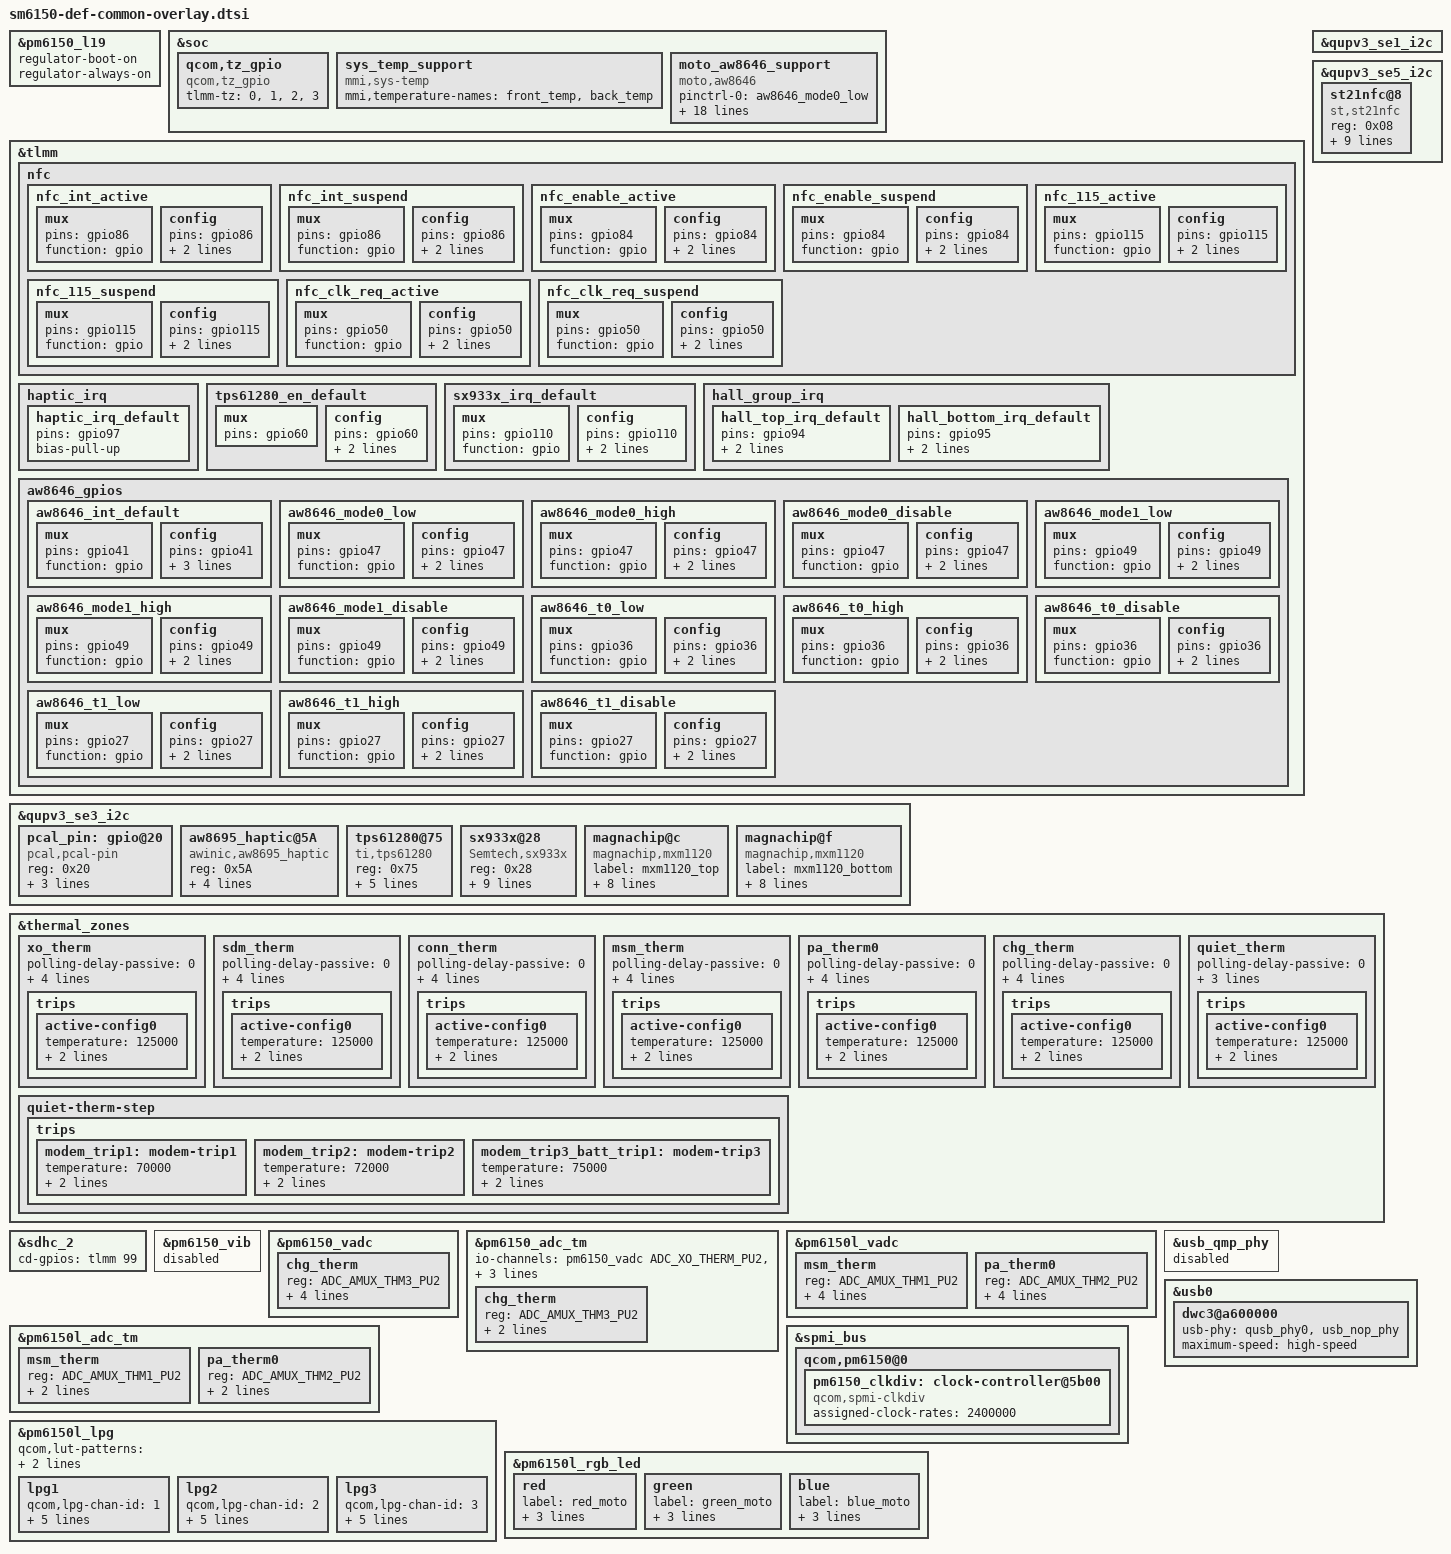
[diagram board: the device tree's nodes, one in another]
/* Copyright (c) 2018, The Linux Foundation. All rights reserved.
 *
 * This program is free software; you can redistribute it and/or modify
 * it under the terms of the GNU General Public License version 2 and
 * only version 2 as published by the Free Software Foundation.
 *
 * This program is distributed in the hope that it will be useful,
 * but WITHOUT ANY WARRANTY; without even the implied warranty of
 * MERCHANTABILITY or FITNESS FOR A PARTICULAR PURPOSE.  See the
 * GNU General Public License for more details.
 */

#include "sm6150-moto-common-overlay.dtsi"
#include "sm6150-audio-overlay.dtsi"
#include "sm6150-def-audio-overlay.dtsi"
#include "sm6150-camera-sensor-mot-def-overlay.dtsi"
#include "sm6150-def-touch-overlay.dtsi"
#include "sm6150-def-fps-overlay.dtsi"
#include "defender-panel.dtsi"

&pm6150_l19 {
	regulator-boot-on;
	regulator-always-on;
	status = "ok";
};

&soc {
	qcom,tz_gpio {
		compatible = "qcom,tz_gpio";
		tlmm-tz = <0>,
			<1>,
			<2>,
			<3>;
	};
};

&tlmm{
	nfc {
		nfc_int_active: nfc_int_active {
			/* active state */
			mux {
				/* GPIO86 NFC Read Interrupt */
				pins = "gpio86";
				function = "gpio";
			};

			config {
				pins = "gpio86";
				bias-disable;
				input-enable;
			};
		};

		nfc_int_suspend: nfc_int_suspend {
			/* sleep state */
			mux {
				/* GPIO 86 NFC Read Interrupt */
				pins = "gpio86";
				function = "gpio";
			};

			config {
				pins = "gpio86";
				bias-disable;
				input-enable;
			};
		};

		nfc_enable_active: nfc_enable_active {
			/* active state */
			mux {
				/* 84: NFC ENABLE */
				pins = "gpio84";
				function = "gpio";
			};

			config {
				pins = "gpio84";
				drive-strength = <2>; /* 2 MA */
				bias-disable;
			};
		};

		nfc_enable_suspend: nfc_enable_suspend {
			/* sleep state */
			mux {
				/* 84: NFC ENABLE */
				pins = "gpio84";
				function = "gpio";
			};

			config {
				pins = "gpio84";
				drive-strength = <2>; /* 2 MA */
				bias-disable;
			};
		};

		nfc_115_active: nfc_115_active {
			/* active state */
			mux {
				/* 84: NFC ENABLE */
				pins = "gpio115";
				function = "gpio";
			};

			config {
				pins = "gpio115";
				drive-strength = <2>; /* 2 MA */
				output-high;
			};
		};

		nfc_115_suspend: nfc_115_suspend {
			/* sleep state */
			mux {
				/* 84: NFC ENABLE */
				pins = "gpio115";
				function = "gpio";
			};

			config {
				pins = "gpio115";
				drive-strength = <2>; /* 2 MA */
				output-high;
			};
		};

		nfc_clk_req_active: nfc_clk_req_active {
			/* active state */
			mux {
				/* 50: NFC CLOCK REQUEST */
				pins = "gpio50";
				function = "gpio";
			};

			config {
				pins = "gpio50";
				bias-disable;
				input-enable;
			};
		};

		nfc_clk_req_suspend: nfc_clk_req_suspend {
			/* sleep state */
			mux {
				/* 50: NFC CLOCK REQUEST */
				pins = "gpio50";
				function = "gpio";
			};

			config {
				pins = "gpio50";
				bias-disable;
				input-enable;
			};
		};
	};

	haptic_irq {
		haptic_irq_default: haptic_irq_default {
			pins = "gpio97";
			bias-pull-up;
		};
	};

        tps61280_en_default: tps61280_en_default {
               mux {
                        pins = "gpio60";
               };
               config {
                        pins = "gpio60";
                        drive_strength = <16>;
                        output-high;
              };
        };

	sx933x_irq_default: sx933x_irq_default {
		mux {
			pins = "gpio110";
			function = "gpio";
		};
		config {
			pins = "gpio110";
			drive-strength = <8>;
			bias-pull-up;
		};
	};

	hall_group_irq {
		hall_top_irq_default: hall_top_irq_default {
			pins = "gpio94";
			drive-strength = <6>;
			bias-pull-up;
		};
		hall_bottom_irq_default: hall_bottom_irq_default {
			pins = "gpio95";
			drive-strength = <6>;
			bias-pull-up;
		};
	};

	aw8646_gpios {
		aw8646_int_default: aw8646_int_default {
			mux {
				pins = "gpio41";
				function = "gpio";
			};

			config {
				pins = "gpio41";
				drive-strength = <6>;
				input-enable;
				bias-disable;
			};
		};
		aw8646_mode0_low: aw8646_mode0_low{
			mux {
				pins = "gpio47";
				function = "gpio";
			};

			config {
				pins = "gpio47";
				drive-strength = <2>; /* 2 MA */
				output-low;
			};
		};
		aw8646_mode0_high: aw8646_mode0_high{
			mux {
				pins = "gpio47";
				function = "gpio";
			};

			config {
				pins = "gpio47";
				drive-strength = <2>; /* 2 MA */
				output-high;
			};
		};
		aw8646_mode0_disable: aw8646_mode0_disable {
			mux {
				pins = "gpio47";
				function = "gpio";
			};

			config {
				pins = "gpio47";
				input-enable;
				bias-disable;
			};
		};
		aw8646_mode1_low: aw8646_mode1_low {
			mux {
				pins = "gpio49";
				function = "gpio";
			};

			config {
				pins = "gpio49";
				drive-strength = <2>; /* 2 MA */
				output-low;
			};
		};
		aw8646_mode1_high: aw8646_mode1_high {
			mux {
				pins = "gpio49";
				function = "gpio";
			};

			config {
				pins = "gpio49";
				drive-strength = <2>; /* 2 MA */
				output-high;
			};
		};
		aw8646_mode1_disable: aw8646_mode1_disable {
			mux {
				pins = "gpio49";
				function = "gpio";
			};

			config {
				pins = "gpio49";
				input-enable;
				bias-disable;
			};
		};
		aw8646_t0_low: aw8646_t0_low {
			mux {
				pins = "gpio36";
				function = "gpio";
			};

			config {
				pins = "gpio36";
				drive-strength = <2>; /* 2 MA */
				output-low;
			};
		};
		aw8646_t0_high: aw8646_t0_high {
			mux {
				pins = "gpio36";
				function = "gpio";
			};

			config {
				pins = "gpio36";
				drive-strength = <2>; /* 2 MA */
				output-high;
			};
		};
		aw8646_t0_disable: aw8646_t0_disable {
			mux {
				pins = "gpio36";
				function = "gpio";
			};

			config {
				pins = "gpio36";
				input-enable;
				bias-disable;
			};
		};
		aw8646_t1_low: aw8646_t1_low {
			mux {
				pins = "gpio27";
				function = "gpio";
			};

			config {
				pins = "gpio27";
				drive-strength = <2>; /* 2 MA */
				output-low;
			};
		};
		aw8646_t1_high: aw8646_t1_high {
			mux {
				pins = "gpio27";
				function = "gpio";
			};

			config {
				pins = "gpio27";
				drive-strength = <2>; /* 2 MA */
				output-high;
			};
		};
		aw8646_t1_disable: aw8646_t1_disable {
			mux {
				pins = "gpio27";
				function = "gpio";
			};

			config {
				pins = "gpio27";
				input-enable;
				bias-disable;
			};
		};
	};
};

&soc {
	sys_temp_support {
		compatible = "mmi,sys-temp";
		mmi,temperature-names = "front_temp",
			"back_temp";
		status = "ok";
	};

	moto_aw8646_support {
		compatible = "moto,aw8646";
		status = "ok";
		pinctrl-names = "m0_low", "m0_high", "m0_disable",
						"m1_low", "m1_high", "m1_disable",
						"t0_low", "t0_high", "t0_disable",
						"t1_low", "t1_high", "t1_disable",
						"aw8646_int_default";
		pinctrl-0 = <&aw8646_mode0_low>;
		pinctrl-1 = <&aw8646_mode0_high>;
		pinctrl-2 = <&aw8646_mode0_disable>;
		pinctrl-3 = <&aw8646_mode1_low>;
		pinctrl-4 = <&aw8646_mode1_high>;
		pinctrl-5 = <&aw8646_mode1_disable>;
		pinctrl-6 = <&aw8646_t0_low>;
		pinctrl-7 = <&aw8646_t0_high>;
		pinctrl-8 = <&aw8646_t0_disable>;
		pinctrl-9 = <&aw8646_t1_low>;
		pinctrl-10 = <&aw8646_t1_high>;
		pinctrl-11 = <&aw8646_t1_disable>;
		pinctrl-12 = <&aw8646_int_default>;
		vdd-supply = <&pm6150_l13>;
		interrupt-parent = <&tlmm>;
		interrupts = <41 0x2002>;
		aw8646-gpios = <116 41 122 37 47 49 26 85 36 27>;
		aw8646-gpios-cells = <10>;
		aw8646-max-freq = <250000>;
	};
};

&qupv3_se1_i2c {
	status = "okay";
};

&qupv3_se3_i2c {
	status = "okay";

	pcal_pin:gpio@20 {
		compatible = "pcal,pcal-pin";
		status = "ok";
		reg = <0x20>;
		gpio-controller;
		#gpio-cells = <2>;
		#address-cells = <1>;
		pcal,pin-num = <16>;
		pcal,reset-gpio = <&tlmm 109 1>;
	};

	aw8695_haptic@5A {
		compatible = "awinic,aw8695_haptic";
		reg = <0x5A>;
		reset-gpio = <&tlmm 113 0>;
		irq-gpio = <&tlmm 97 0>;
		haptic-context-gpio = <&tlmm 101 0>;
		pinctrl-names = "default";
		pinctrl-0 = <&haptic_irq_default>;
		status = "okay";
	};

        tps61280@75 {
                compatible = "ti,tps61280";
                reg = <0x75>;
                ti,config = <0x0D>;
                ti,vout-floor = <0x0F>;
                ti,vout-roof = <0x1F>;
                ti,ilim = <0x0F>;
                pinctrl-names = "default";
                pinctrl-0 = <&tps61280_en_default>;
        };

	sx933x@28 {
		compatible = "Semtech,sx933x";
		reg = <0x28>;
		interrupt-parent = <&tlmm>;
		interrupts = <110 0x2008>;
		Semtech,nirq-gpio = <&tlmm 110 0x2008>;
		pinctrl-names = "default";
		pinctrl-0 = <&sx933x_irq_default>;
		cap_vdd-supply = <&pm6150l_l7>;
		Semtech,button-flag = <0x07>;
		Semtech,reg-num = <44>;
		Semtech,reg-init = <
			0x4004 0x77
			0x4054 0x400
			0x42C0 0x8000000
			0x42C4 0x3F
			0x801C 0x31
			0x8024 0x3001A46 /*again 6.6pf*/
			0x8028 0x3FFE8262
			0x802c 0x130006BF
			0x8030 0x3FF78258
			0x8034 0x3000C46
			0x8038 0x3FBF8269
			0x803c 0x130006BF
			0x8040 0x3DFF825D
			0x8044 0x88E
			0x8048 0x280002D4
			0x804C 0x88E
			0x8050 0x80001EE6
			0x8054 0x10124000 /*ph0*/
			0x8058 0x60600D31
			0x805c 0x54AC4300
			0x8064 0x00AD0000 /*5mm th*/
			0x8074 0x10223900 /*ph1*/
			0x8078 0x60600D31
			0x807c 0x54AC4300
			0x8084 0x009E0000 /*5mm th*/
			0x808C 0x1F001F00
			0x8090 0x00010000
			0x8094 0x10123900 /*ph2*/
			0x8098 0x60600D31
			0x809C 0x54AC4300
			0x80A4 0x00B30000 /*5mm th*/
			0x80B4 0x10027E00
			0x80B8 0x60600931
			0x80bc 0x54AC4300
			0x80D4 0x10162800
			0x80D8 0x20400031
			0x80DC 0x54AC5300
			0x80E4 0x62623B
			0x80F4 0x10162800
			0x80F8 0x20400031
			0x80FC 0x54AC5300
			0x8124 0x400000B
			0x81A4 0x1C40009
			0x8020 0x000F0000
		>;
	};

	magnachip@c {
		compatible = "magnachip,mxm1120";
		label = "mxm1120_top";
		reg = <0x0c>;
		pinctrl-names = "default";
		pinctrl-0 = <&hall_top_irq_default>;
		interrupt-parent = <&tlmm>;
		interrupts = <94 0x2002>;
		vdd-supply = <&pm6150_l5>;
		vio-supply = <&pm6150_l13>;
		magnachip,init-interval = <200>;
		magnachip,gpio-int = <&tlmm 94 0x2002>;
		/* magnachip,use-hrtimer; */
	};

	magnachip@f { // Hall Sensor
		compatible = "magnachip,mxm1120";
		label = "mxm1120_bottom";
		reg = <0x0f>;
		pinctrl-names = "default";
		pinctrl-0 = <&hall_bottom_irq_default>;
		interrupt-parent = <&tlmm>;
		interrupts = <95 0x2002>;
		vdd-supply = <&pm6150_l5>;
		vio-supply = <&pm6150_l13>;
		magnachip,init-interval = <200>;
		magnachip,gpio-int = <&tlmm 95 0x2002>;
		/* magnachip,use-hrtimer; */
	};
};

&qupv3_se5_i2c {
	status = "ok";
	st21nfc@8 {
		compatible = "st,st21nfc";
		status = "ok";
		reg = <0x08>;
		st,irq_gpio = <&tlmm 86 0x00>;
		st,reset_gpio = <&tlmm 84 0x00>;
		st,clkreq_gpio = <&tlmm 50 0x00>;
		interrupt-parent = <&tlmm>;
		interrupts = <86 0>;
		interrupt-names = "nfc_irq";
		pinctrl-names = "nfc_active", "nfc_suspend";
		pinctrl-0 = <&nfc_int_active &nfc_enable_active &nfc_clk_req_active>;
		pinctrl-1 = <&nfc_int_suspend &nfc_enable_suspend &nfc_clk_req_suspend>;
	};
};

&thermal_zones {
	xo_therm {
		polling-delay-passive = <0>;
		polling-delay = <0>;
		thermal-governor = "user_space";
		thermal-sensors = <&pm6150_adc_tm ADC_XO_THERM_PU2>;
		trips {
			active-config0 {
				temperature = <125000>;
				hysteresis = <1000>;
				type = "passive";
			};
		};
	};

	sdm_therm {
		polling-delay-passive = <0>;
		polling-delay = <0>;
		thermal-governor = "user_space";
		thermal-sensors = <&pm6150_adc_tm ADC_AMUX_THM2_PU2>;
		trips {
			active-config0 {
				temperature = <125000>;
				hysteresis = <1000>;
				type = "passive";
			};
		};
	};

	conn_therm {
		polling-delay-passive = <0>;
		polling-delay = <0>;
		thermal-governor = "user_space";
		thermal-sensors = <&pm6150_adc_tm ADC_AMUX_THM4_PU2>;
		trips {
			active-config0 {
				temperature = <125000>;
				hysteresis = <1000>;
				type = "passive";
			};
		};
	};

	msm_therm {
		polling-delay-passive = <0>;
		polling-delay = <0>;
		thermal-governor = "user_space";
		thermal-sensors = <&pm6150_adc_tm ADC_AMUX_THM2_PU2>;
		trips {
			active-config0 {
				temperature = <125000>;
				hysteresis = <1000>;
				type = "passive";
			};
		};
	};

	pa_therm0 {
		polling-delay-passive = <0>;
		polling-delay = <0>;
		thermal-governor = "user_space";
		thermal-sensors = <&pm6150l_adc_tm ADC_AMUX_THM2_PU2>;
		trips {
			active-config0 {
				temperature = <125000>;
				hysteresis = <1000>;
				type = "passive";
			};
		};
	};

	chg_therm {
		polling-delay-passive = <0>;
		polling-delay = <0>;
		thermal-governor = "user_space";
		thermal-sensors = <&pm6150_adc_tm ADC_AMUX_THM3_PU2>;
		trips {
			active-config0 {
				temperature = <125000>;
				hysteresis = <1000>;
				type = "passive";
			};
		};
	};

	quiet_therm {
		polling-delay-passive = <0>;
		polling-delay = <0>;
		thermal-governor = "user_space";
		thermal-sensors = <&pm6150l_adc_tm ADC_GPIO4_PU2>;
		trips {
			active-config0 {
				temperature = <125000>;
				hysteresis = <1000>;
				type = "passive";
			};
		};
	};
	quiet-therm-step {
		trips {
			modem_trip1: modem-trip1 {
				temperature = <70000>;
				hysteresis = <2000>;
				type = "passive";
			};
			modem_trip2: modem-trip2 {
				temperature = <72000>;
				hysteresis = <2000>;
				type = "passive";
			};
			modem_trip3_batt_trip1: modem-trip3 {
				temperature = <75000>;
				hysteresis = <2000>;
				type = "passive";
			};
		};
	};
};

&sdhc_2 {
	cd-gpios = <&tlmm 99 0x0>;
};

&pm6150_vib {
	status = "disable";
};

&pm6150_vadc {
	chg_therm {
		reg = <ADC_AMUX_THM3_PU2>;
		label = "chg_therm";
		qcom,ratiometric;
		qcom,hw-settle-time = <200>;
		qcom,pre-scaling = <1 1>;
	};
};

&pm6150_adc_tm {
	io-channels = <&pm6150_vadc ADC_XO_THERM_PU2>,
			<&pm6150_vadc ADC_AMUX_THM2_PU2>,
			<&pm6150_vadc ADC_AMUX_THM3_PU2>,
			<&pm6150_vadc ADC_AMUX_THM4_PU2>;

	/* Channel nodes */
	chg_therm {
		reg = <ADC_AMUX_THM3_PU2>;
		qcom,ratiometric;
		qcom,hw-settle-time = <200>;
	};
};

&pm6150l_vadc {
	msm_therm {
		reg = <ADC_AMUX_THM1_PU2>;
		label = "msm_therm";
		qcom,ratiometric;
		qcom,hw-settle-time = <200>;
		qcom,pre-scaling = <1 1>;
	};

	pa_therm0 {
		reg = <ADC_AMUX_THM2_PU2>;
		label = "pa_therm0";
		qcom,ratiometric;
		qcom,hw-settle-time = <200>;
		qcom,pre-scaling = <1 1>;
	};
};

&pm6150l_adc_tm {
	/* Channel nodes */
	msm_therm {
		reg = <ADC_AMUX_THM1_PU2>;
		qcom,ratiometric;
		qcom,hw-settle-time = <200>;
	};

	pa_therm0 {
		reg = <ADC_AMUX_THM2_PU2>;
		qcom,ratiometric;
		qcom,hw-settle-time = <200>;
	};
};

&usb_qmp_phy {
	status = "disabled";
};

&usb0 {
	dwc3@a600000 {
		usb-phy = <&qusb_phy0>, <&usb_nop_phy>;
		maximum-speed = "high-speed";
	};
};

&spmi_bus {
	qcom,pm6150@0 {
		pm6150_clkdiv: clock-controller@5b00 {
			compatible = "qcom,spmi-clkdiv";
			assigned-clock-rates = <2400000>;
		};
	};
};

&pm6150l_lpg {
	qcom,lut-patterns = <0 3 6 9 12 15 18 21 24 27 30 34 38 42 46 50 55 60 65 70 80 90 100
			     100 90 80 70 65 60 55 50 46 42 38 34 30 27 24 21 18 15 12 9 6 3 0>;
	qcom,sync-channel-ids = <1 2 3>;
	lpg1 {
		qcom,lpg-chan-id = <1>;
		qcom,ramp-step-ms = <50>;
		qcom,ramp-pause-hi-count = <2>;
		qcom,ramp-pause-lo-count = <2>;
		qcom,ramp-low-index = <0>;
		qcom,ramp-high-index = <45>;
	};
	lpg2 {
		qcom,lpg-chan-id = <2>;
		qcom,ramp-step-ms = <50>;
		qcom,ramp-pause-hi-count = <2>;
		qcom,ramp-pause-lo-count = <2>;
		qcom,ramp-low-index = <0>;
		qcom,ramp-high-index = <45>;
	};
	lpg3 {
		qcom,lpg-chan-id = <3>;
		qcom,ramp-step-ms = <50>;
		qcom,ramp-pause-hi-count = <2>;
		qcom,ramp-pause-lo-count = <2>;
		qcom,ramp-low-index = <0>;
		qcom,ramp-high-index = <45>;
	};
};

&pm6150l_rgb_led {
	red {
		label = "red_moto";
		pwms = <&pm6150l_lpg 0 1000000>;
		led-sources = <0>;
		linux,default-trigger = "timer";
	};
	green {
		label = "green_moto";
		pwms = <&pm6150l_lpg 1 1000000>;
		led-sources = <1>;
		linux,default-trigger = "timer";
	};
	blue {
		label = "blue_moto";
		pwms = <&pm6150l_lpg 2 1000000>;
		led-sources = <2>;
		linux,default-trigger = "timer";
	};
};
